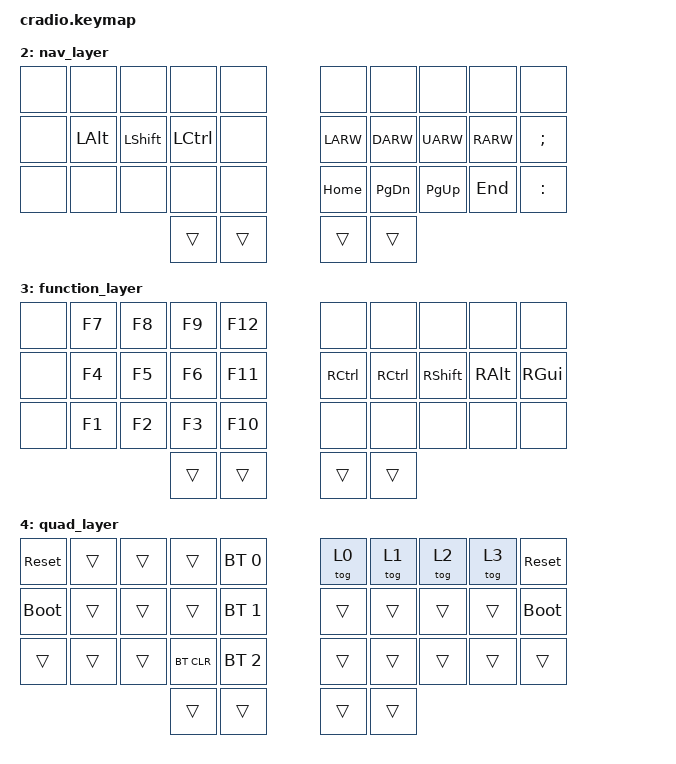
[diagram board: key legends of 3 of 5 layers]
// Copyright (c) 2022 The ZMK Contributors
// SPDX-License-Identifier: MIT

#include <behaviors.dtsi>
#include <dt-bindings/zmk/keys.h>
#include <dt-bindings/zmk/bt.h>

// Home row mods macro
#define HRML(k1,k2,k3,k4) &ht LGUI  k1  &ht LALT  k2  &ht LSHFT k3  &ht LCTRL k4
#define HRMR(k1,k2,k3,k4) &ht RCTRL k1  &ht RSHFT k2  &ht RALT  k3  &ht RGUI  k4

/ {

    combos {
        compatible = "zmk,combos";
        combo_tab {
            timeout-ms = <50>;
            key-positions = <11 12>;
            bindings = <&kp TAB>;
        };
       	
        combo_bspc {
            timeout-ms = <50>;
            key-positions = <17 18>;
            bindings = <&kp BSPC>;
        };
    };

    behaviors {
        ht: hold_tap {
            compatible = "zmk,behavior-hold-tap";
            #binding-cells = <2>;
            flavor = "tap-preferred";
            tapping-term-ms = <220>;
            quick-tap-ms = <150>;
            require-prior-idle-ms = <100>;
            bindings = <&kp>, <&kp>;
        };
    };

    conditional_layers {
        compatible = "zmk,conditional-layers";
        tri_layer {
            if-layers = <1 2>;
            then-layer = <4>;
        };
    };

    keymap {
        compatible = "zmk,keymap";
        default_layer {
            bindings = <
        //╭──────────┬──────────┬──────────┬──────────┬──────────╮   ╭──────────┬──────────┬──────────┬──────────┬──────────╮
        //│  Q       │  W       │  E       │  R       │  T       │   │  Y       │  U       │  I       │  O       │  P       │
            &kp Q      &kp W      &kp E      &kp R      &kp T          &kp Y      &kp U      &kp I      &kp O      &kp P
        //├──────────┼──────────┼──────────┼──────────┼──────────┤   ├──────────┼──────────┼──────────┼──────────┼──────────┤
        //│  A       │  S       │  D       │  F       │  G       │   │  H       │  J       │  K       │  L       │ ' "      │
            HRML(A,        S,         D,         F)     &kp G          &kp H      HRMR(J,        K,         L,        SQT)
        //├──────────┼──────────┼──────────┼──────────┼──────────┤   ├──────────┼──────────┼──────────┼──────────┼──────────┤
        //│  Z       │  X       │  C       │  V       │  B       │   │  N       │  M       │ , <      │ . >      │ / ?      │
            &kp Z      &kp X      &kp C      &kp V      &kp B          &kp N      &kp M      &kp COMMA  &kp DOT    &kp FSLH
        //╰──────────┴──────────┴──────────┼──────────┼──────────┤   ├──────────┼──────────┼──────────┴──────────┴──────────╯
                                            &lt 2 SPACE  &kp ESC      &lt 3 DEL  &lt 1 ENTER
        //                                 ╰──────────┴──────────╯   ╰──────────┴──────────╯
            >;
        };

        number_layer {
            bindings = <
        //╭──────────┬──────────┬──────────┬──────────┬──────────╮   ╭──────────┬──────────┬──────────┬──────────┬──────────╮
        //│ INSERT   │  7       │  8       │  9       │    -     │   │  `       │  {       │  }       │  +       │  ~       │
            &kp INS    &kp N7     &kp N8     &kp N9    &kp MINUS        &kp GRAVE  &kp LBRC   &kp RBRC   &kp PLUS   &kp TILDE
        //├──────────┼──────────┼──────────┼──────────┼──────────┤   ├──────────┼──────────┼──────────┼──────────┼──────────┤
        //│ DELETE   │  4       │  5       │  6       │    =     │   │  ,       │  (       │  )       │  \       │  `       │
            HRML(DEL,     N4,        N5,       N6)     &kp EQUAL      &kp COMMA  HRMR(LPAR,   RPAR,     BSLH,      GRAVE)
        //├──────────┼──────────┼──────────┼──────────┼──────────┤   ├──────────┼──────────┼──────────┼──────────┼──────────┤
        //│ CAPS     │  1       │  2       │  3       │  0       │   │  '       │  [       │  ]       │  │       │          │
           &caps_word  &kp N1     &kp N2     &kp N3     &kp N0         &kp SQT   &kp LBKT   &kp RBKT   &kp PIPE   &trans
        //╰──────────┴──────────┴──────────┼──────────┼──────────┤   ├──────────┼──────────┼──────────┴──────────┴──────────╯
                                             &trans     &kp ESC        &trans     &trans
        //                                 ╰──────────┴──────────╯   ╰──────────┴──────────╯
            >;
        };

        nav_layer {
            bindings = <
        //╭──────────┬──────────┬──────────┬──────────┬──────────╮   ╭──────────┬──────────┬──────────┬──────────┬──────────╮
        //│          │          │          │          │          │   │          │          │          │          │          │
            &none       &none      &none      &none       &none         &none       &none      &none     &none      &none
        //├──────────┼──────────┼──────────┼──────────┼──────────┤   ├──────────┼──────────┼──────────┼──────────┼──────────┤
        //│          │  ALT     │  SHIFT   │  Ctrl    │          │   │ LEFT     │ DOWN     │ UP       │ RIGHT    │  ;       │
            &none     &kp LALT   &kp LSHFT   &kp LCTRL   &none         &kp LARW   &kp DARW  &kp UARW    &kp RARW   &kp SEMI
        //├──────────┼──────────┼──────────┼──────────┼──────────┤   ├──────────┼──────────┼──────────┼──────────┼──────────┤
        //│          │          │          │          │          │   │ HOME     │ PAGE DN  │ PAGE UP  │ END      │  :       │
            &none       &none       &none     &none      &none         &kp HOME  &kp PG_DN  &kp PG_UP   &kp END    &kp COLON
        //╰──────────┴──────────┴──────────┼──────────┼──────────┤   ├──────────┼──────────┼──────────┴──────────┴──────────╯
                                             &trans     &trans         &trans     &trans
        //                                 ╰──────────┴──────────╯   ╰──────────┴──────────╯
            >;
        };

        function_layer {
            bindings = <
        //╭──────────┬──────────┬──────────┬──────────┬──────────╮   ╭──────────┬──────────┬──────────┬──────────┬──────────╮
        //│          │    F7    │   F8     │   F9     │   F12    │   │          │          │          │          │          │
            &none       &kp F7     &kp F8     &kp F9     &kp F12         &none       &none      &none     &none      &none
        //├──────────┼──────────┼──────────┼──────────┼──────────┤   ├──────────┼──────────┼──────────┼──────────┼──────────┤
        //│          │    F4    │    F5    │   F6     │   F11    │   │ LEFT     │ DOWN     │ UP       │ RIGHT    │  ;       │
            &none       &kp F4     &kp F5     &kp F6   &kp F11        &kp RCTRL  &kp RCTRL  &kp RSHFT    &kp RALT   &kp RGUI
        //├──────────┼──────────┼──────────┼──────────┼──────────┤   ├──────────┼──────────┼──────────┼──────────┼──────────┤
        //│          │    F1    │    F2    │   F3     │   F10    │   │          │          │          │          │  :       │
            &none       &kp F1     &kp F2     &kp F3      &kp F10        &none       &none      &none     &none      &none
        //╰──────────┴──────────┴──────────┼──────────┼──────────┤   ├──────────┼──────────┼──────────┴──────────┴──────────╯
                                             &trans      &trans         &trans     &trans
        //                                 ╰──────────┴──────────╯   ╰──────────┴──────────╯
            >;
        };

        quad_layer {
            bindings = <
        //╭──────────┬──────────┬──────────┬──────────┬──────────╮   ╭──────────┬──────────┬──────────┬──────────┬──────────╮
        //│ RESET    │          │          │          │PROFILE 0 │   │          │          │          │          │  RESET   │
           &sys_reset  &trans     &trans     &trans    &bt BT_SEL 0    &tog 0     &tog 1     &tog 2     &tog 3    &sys_reset
        //├──────────┼──────────┼──────────┼──────────┼──────────┤   ├──────────┼──────────┼──────────┼──────────┼──────────┤
        //│BOOTLOADER│          │          │          │PROFILE 1 │   │          │          │          │          │BOOTLOADER│
          &bootloader  &trans     &trans     &trans    &bt BT_SEL 1    &trans     &trans     &trans     &trans    &bootloader
        //├──────────┼──────────┼──────────┼──────────┼──────────┤   ├──────────┼──────────┼──────────┼──────────┼──────────┤
        //│          │          │          │ CLEAR BT │PROFILE 2 │   │          │          │          │          │          │
            &trans     &trans     &trans    &bt BT_CLR &bt BT_SEL 2    &trans     &trans     &trans     &trans     &trans
        //╰──────────┴──────────┴──────────┼──────────┼──────────┤   ├──────────┼──────────┼──────────┴──────────┴──────────╯
                                             &trans     &trans         &trans     &trans
        //                                 ╰──────────┴──────────╯   ╰──────────┴──────────╯
            >;
        };
    };
};
